# CC3220SF register map
Vendor: Texas Instruments; Series: Wireless Connectivity MCU; File version: 1
CPU: CM4 r1p0, little endian, no MPU, no FPU, 8 interrupt priority bits
Registers are 32-bit, read-write, reset 0x0 unless marked. A register's access mark holds for its fields unless they carry their own. Offsets are from the block's base; [hi:lo] are bit positions; {n}, {i} and the like mark numbered series.

## SHAMD5
Base 0x44035000
0x00 ODIGEST_A — WRITE: Outer Digest [127:96] for MD5 [159:128] for SHA-1 [255:224] for SHA-2 / HMAC Key [31:0] for HMAC key proc READ: Outer Digest [127:96] for MD5 [159:128] for SHA-1 [255:224] for SHA-2
0x04 ODIGEST_B — WRITE: Outer Digest [95:64] for MD5 [127:96] for SHA-1 [223:192] for SHA-2 / HMAC Key [63:32] for HMAC key proc READ: Outer Digest [95:64] for MD5 [127:96] for SHA-1 [223:192] for SHA-2
0x08 ODIGEST_C — WRITE: Outer Digest [63:32] for MD5 [95:64] for SHA-1 [191:160] for SHA-2 / HMAC Key [95:64] for HMAC key proc READ: Outer Digest [63:32] for MD5 [95:64] for SHA-1 [191:160] for SHA-2
0x0C ODIGEST_D — WRITE: Outer Digest [31:0] for MD5 [63:31] for SHA-1 [159:128] for SHA-2 / HMAC Key [127:96] for HMAC key proc READ: Outer Digest [31:0] for MD5 [63:32] for SHA-1 [159:128] for SHA-2
0x10 ODIGEST_E — WRITE: Outer Digest [31:0] for SHA-1 [127:96] for SHA-2 / HMAC Key [159:128] for HMAC key proc READ: Outer Digest [31:0] for SHA-1 [127:96] for SHA-2
0x14 ODIGEST_F — WRITE: Outer Digest [95:64] for SHA-2 / HMAC Key [191:160] for HMAC key proc READ: Outer Digest [95:64] for SHA-2
0x18 ODIGEST_G — WRITE: Outer Digest [63:32] for SHA-2 / HMAC Key [223:192] for HMAC key proc READ: Outer Digest [63:32] for SHA-2
0x1C ODIGEST_H — WRITE: Outer Digest [31:0] for SHA-2 / HMAC Key [255:224] for HMAC key proc READ: Outer Digest [31:0] for SHA-2
0x20 IDIGEST_A — WRITE: Inner / Initial Digest [127:96] for MD5 [159:128] for SHA-1 [255:224] for SHA-2 / HMAC Key [287:256] for HMAC key proc READ: Intermediate / Inner Digest [127:96] for MD5 [159:128] for SHA-1 [255:224] for SHA-2 / Result Digest/MAC [127:96] for MD5 [159:128] for SHA-1 [223:192] for SHA-2 224 [255:224] for SHA-2 256
0x24 IDIGEST_B — WRITE: Inner / Initial Digest [95:64] for MD5 [127:96] for SHA-1 [223:192] for SHA-2 / HMAC Key [319:288] for HMAC key proc READ: Intermediate / Inner Digest [95:64] for MD5 [127:96] for SHA-1 [223:192] for SHA-2 / Result Digest/MAC [95:64] for MD5 [127:96] for SHA-1 [191:160] for SHA-2 224 [223:192] for SHA-2 256
0x28 IDIGEST_C — WRITE: Inner / Initial Digest [63:32] for MD5 [95:64] for SHA-1 [191:160] for SHA- 2 / HMAC Key [351:320] for HMAC key proc READ: Intermediate / Inner Digest [63:32] for MD5 [95:64] for SHA-1 [191:160] for SHA-2 / Result Digest/MAC [63:32] for MD5 [95:64] for SHA-1 [159:128] for SHA-2 224 [191:160] for SHA-2 256
0x2C IDIGEST_D — WRITE: Inner / Initial Digest [31:0] for MD5 [63:32] for SHA-1 [159:128] for SHA-2 / HMAC Key [383:352] for HMAC key proc READ: Intermediate / Inner Digest [31:0] for MD5 [63:32] for SHA-1 [159:128] for SHA-2 / Result Digest/MAC [31:0] for MD5 [63:32] for SHA-1 [127:96] for SHA-2 224 [159:128] for SHA-2 256
0x30 IDIGEST_E — WRITE: Inner / Initial Digest [31:0] for SHA-1 [127:96] for SHA-2 / HMAC Key [415:384] for HMAC key proc READ: Intermediate / Inner Digest [31:0] for SHA-1 [127:96] for SHA-2 / Result Digest/MAC [31:0] for SHA-1 [95:64] for SHA-2 224 [127:96] for SHA-2 256
0x34 IDIGEST_F — WRITE: Inner / Initial Digest [95:64] for SHA-2 / HMAC Key [447:416] for HMAC key proc READ: Intermediate / Inner Digest [95:64] for SHA-2 / Result Digest/MAC [63:32] for SHA-2 224 [95:64] for SHA-2 256
0x38 IDIGEST_G — WRITE: Inner / Initial Digest [63:32] for SHA-2 / HMAC Key [479:448] for HMAC key proc READ: Intermediate / Inner Digest [63:32] for SHA-2 / Result Digest/MAC [31:0] for SHA-2 224 [63:32] for SHA-2 256
0x3C IDIGEST_H — WRITE: Inner / Initial Digest [31:0] for SHA-2 / HMAC Key [511:480] for HMAC key proc READ: Intermediate / Inner Digest [31:0] for SHA-2 / Result Digest/MAC [31:0] for SHA-2 256
0x40 DIGEST_COUNT — WRITE: Initial Digest Count ([31:6] only [5:0] assumed 0) READ: Result / IntermediateDigest Count The initial digest byte count for hash/HMAC continue operations (HMAC Key Processing = 0 and Use Algorithm Constants = 0) on the Secure World must be written to this register prior to starting the operation by writing to S_HASH_MODE. When either HMAC Key Processing is 1 or Use Algorithm Constants is 1 this register does not need to be written it will be overwritten with 64 (1 hash block of key XOR ipad) or 0 respectively automatically. When starting a HMAC operation from pre-computes (HMAC Key Processing is 0) then the value 64 must be written here to compensate for the appended key XOR ipad block. Note that the value written should always be a 64 byte multiple the lower 6 bits written are ignored. The updated digest byte count (initial digest byte count + bytes processed) can be read from this register when the status register indicates that the operation is done or suspended due to a context switch request or when a Secure World context out DMA is requested. In Advanced DMA mode when not suspended with a partial result reading the SHAMD5_DIGEST_COUNT register triggers the Hash/HMAC Engine to start the next context input DMA. Therefore reading the SHAMD5_DIGEST_COUNT register should always be the last context-read action if not suspended with a partial result (i.e. PartHashReady interrupt not pending).
0x44 MODE — Register SHAMD5_MODE
  [2:1] ALGO — These bits select the hash algorithm to be used for processing: 0x0 md5_128 algorithm 0x1 sha1_160 algorithm 0x2 sha2_224 algorithm 0x3 sha2_256 algorithm
0x48 LENGTH — WRITE: Block Length / Remaining Byte Count (bytes) READ: Remaining Byte Count. The value programmed MUST be a 64-byte multiple if Close Hash is set to 0. This register is also the trigger to start processing: once this register is written the core will commence requesting input data via DMA or IRQ (if programmed length > 0) and start processing. The remaining byte count for the active operation can be read from this register when the interrupt status register indicates that the operation is suspended due to a context switch request.
{0x80+4i} DATA{i}_IN (i=0..15) — Data input message {i}
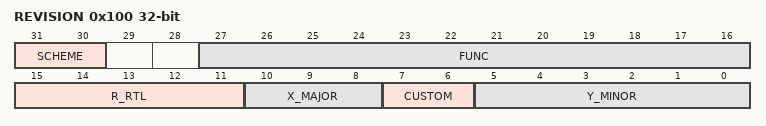
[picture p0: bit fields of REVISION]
0x100 REVISION — Register SHAMD5_REV
  [31:30] SCHEME
  [27:16] FUNC — Function indicates a software compatible module family. If there is no level of software compatibility a new Func number (and hence REVISION) should be assigned.
  [15:11] R_RTL — RTL Version (R) maintained by IP design owner. RTL follows a numbering such as X.Y.R.Z which are explained in this table. R changes ONLY when: (1) PDS uploads occur which may have been due to spec changes (2) Bug fixes occur (3) Resets to '0' when X or Y changes. Design team has an internal 'Z' (customer invisible) number which increments on every drop that happens due to DV and RTL updates. Z resets to 0 when R increments.
  [10:8] X_MAJOR — Major Revision (X) maintained by IP specification owner. X changes ONLY when: (1) There is a major feature addition. An example would be adding Master Mode to Utopia Level2. The Func field (or Class/Type in old PID format) will remain the same. X does NOT change due to: (1) Bug fixes (2) Change in feature parameters.
  [7:6] CUSTOM
  [5:0] Y_MINOR — Minor Revision (Y) maintained by IP specification owner. Y changes ONLY when: (1) Features are scaled (up or down). Flexibility exists in that this feature scalability may either be represented in the Y change or a specific register in the IP that indicates which features are exactly available. (2) When feature creeps from Is-Not list to Is list. But this may not be the case once it sees silicon; in which case X will change. Y does NOT change due to: (1) Bug fixes (2) Typos or clarifications (3) major functional/feature change/addition/deletion. Instead these changes may be reflected via R S X as applicable. Spec owner maintains a customer-invisible number 'S' which changes due to: (1) Typos/clarifications (2) Bug documentation. Note that this bug is not due to a spec change but due to implementation. Nevertheless the spec tracks the IP bugs. An RTL release (say for silicon PG1.1) that occurs due to bug fix should document the corresponding spec number (X.Y.S) in its release notes.
0x110 SYSCONFIG — Register SHAMD5_SYSCONFIG
0x114 SYSSTATUS — Register SHAMD5_SYSSTATUS
0x118 IRQSTATUS — Register SHAMD5_IRQSTATUS
0x11C IRQENABLE — Register SHAMD5_IRQENABLE. The SHAMD5_IRQENABLE register contains an enable bit for each unique interrupt for the public side. An interrupt is enabled when both the global enable in SHAMD5_SYSCONFIG (PIT_en) and the bit in this register are both set to 1. An interrupt that is enabled is propagated to the SINTREQUEST_P output. Please note that the dedicated partial hash output (SINTREQUEST_PART_P) is not affected by this register it is only affected by the global enable SHAMD5_SYSCONFIG (PIT_en).
0x200 HASH512_ODIGEST_A
0x204 HASH512_ODIGEST_B
0x208 HASH512_ODIGEST_C
0x20C HASH512_ODIGEST_D
0x210 HASH512_ODIGEST_E
0x214 HASH512_ODIGEST_F
0x218 HASH512_ODIGEST_G
0x21C HASH512_ODIGEST_H
0x220 HASH512_ODIGEST_I
0x224 HASH512_ODIGEST_J
0x228 HASH512_ODIGEST_K
0x22C HASH512_ODIGEST_L
0x230 HASH512_ODIGEST_M
0x234 HASH512_ODIGEST_N
0x238 HASH512_ODIGEST_O
0x23C HASH512_ODIGEST_P
0x240 HASH512_IDIGEST_A
0x244 HASH512_IDIGEST_B
0x248 HASH512_IDIGEST_C
0x24C HASH512_IDIGEST_D
0x250 HASH512_IDIGEST_E
0x254 HASH512_IDIGEST_F
0x258 HASH512_IDIGEST_G
0x25C HASH512_IDIGEST_H
0x260 HASH512_IDIGEST_I
0x264 HASH512_IDIGEST_J
0x268 HASH512_IDIGEST_K
0x26C HASH512_IDIGEST_L
0x270 HASH512_IDIGEST_M
0x274 HASH512_IDIGEST_N
0x278 HASH512_IDIGEST_O
0x27C HASH512_IDIGEST_P
0x280 HASH512_DIGEST_COUNT
0x284 HASH512_MODE
0x288 HASH512_LENGTH
